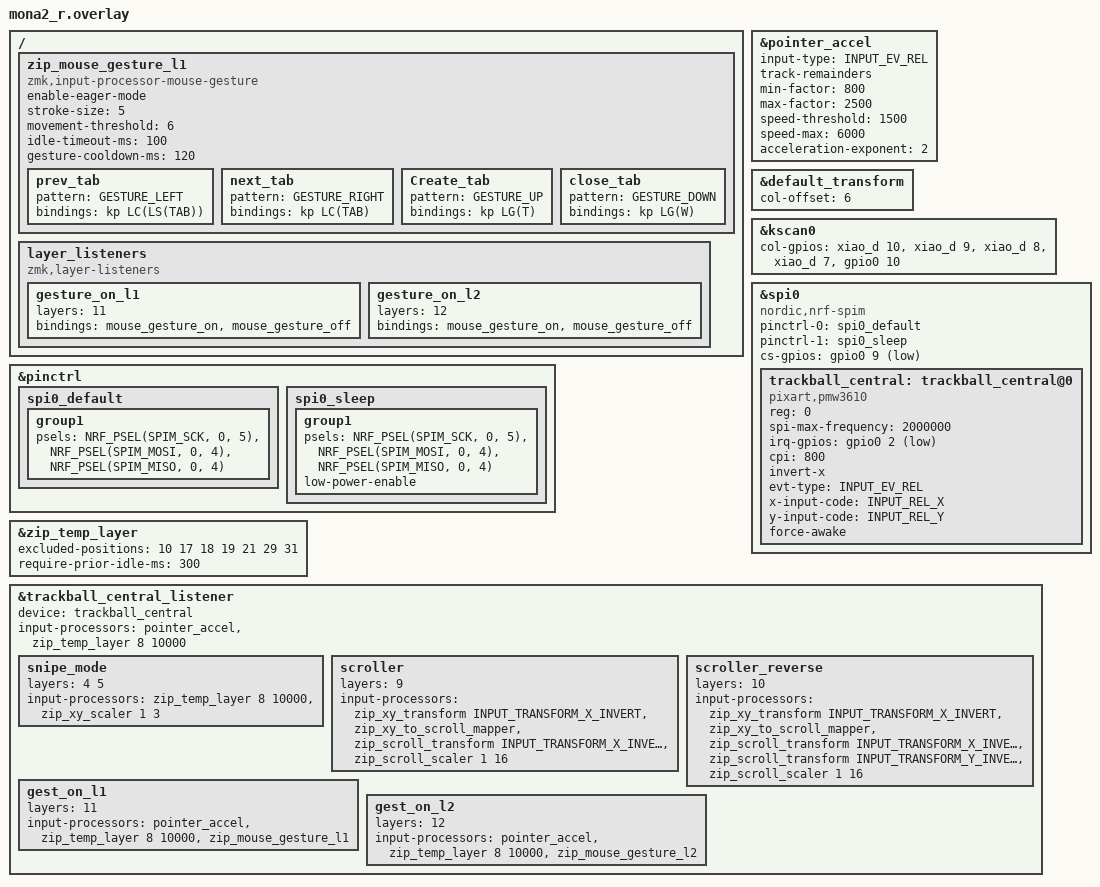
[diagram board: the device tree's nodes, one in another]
#include "mona2.dtsi"
#include <input/processors.dtsi>
#include <zephyr/dt-bindings/input/input-event-codes.h>
#include <input/processors.dtsi>
#include <behaviors/input_gestures_accel.dtsi>
#include <mouse-gesture.dtsi>   /* kot149 モジュール */

// =========================================================================
// ジェスチャーモジュールの定義（ここが重要です）
// =========================================================================
/ {
    zip_mouse_gesture_l1: zip_mouse_gesture_l1 {
        compatible = "zmk,input-processor-mouse-gesture";
        #input-processor-cells = <0>; 
        enable-eager-mode;
        stroke-size = <5>;
        movement-threshold = <6>;
        idle-timeout-ms = <100>;
        gesture-cooldown-ms = <120>;

        prev_tab    { pattern = <GESTURE_LEFT>;  bindings = <&kp LC(LS(TAB))>; };
        next_tab    { pattern = <GESTURE_RIGHT>; bindings = <&kp LC(TAB)>;     };
        Create_tab  { pattern = <GESTURE_UP>;    bindings = <&kp LG(T)>;       };
        close_tab   { pattern = <GESTURE_DOWN>;  bindings = <&kp LG(W)>;       };
    };
};

// =========================================================================
// ★追加：加速度（アクセラレーション）のカーブ設定
// =========================================================================
&pointer_accel {
    input-type = <INPUT_EV_REL>;
    track-remainders;
    min-factor = <800>;
    max-factor = <2500>;
    speed-threshold = <1500>;
    speed-max = <6000>;
    acceleration-exponent = <2>;
};

&default_transform {
    col-offset = <6>;
};

&kscan0 {
        col-gpios
            = <&xiao_d 10 GPIO_ACTIVE_HIGH>
            , <&xiao_d 9 GPIO_ACTIVE_HIGH> 
            , <&xiao_d 8 GPIO_ACTIVE_HIGH> 
            , <&xiao_d 7 GPIO_ACTIVE_HIGH> 
            , <&gpio0 10 GPIO_ACTIVE_HIGH>
            ;
};

&pinctrl {
    spi0_default: spi0_default {
        group1 {
            psels = <NRF_PSEL(SPIM_SCK, 0, 5)>,
                <NRF_PSEL(SPIM_MOSI, 0, 4)>,
                <NRF_PSEL(SPIM_MISO, 0, 4)>;
        };
    };

    spi0_sleep: spi0_sleep {
        group1 {
            psels = <NRF_PSEL(SPIM_SCK, 0, 5)>,
                <NRF_PSEL(SPIM_MOSI, 0, 4)>,
                <NRF_PSEL(SPIM_MISO, 0, 4)>;
            low-power-enable;
        };
    };
};

&spi0 {
    status = "okay";
    compatible = "nordic,nrf-spim";
    pinctrl-0 = <&spi0_default>;
    pinctrl-1 = <&spi0_sleep>;
    pinctrl-names = "default", "sleep";
    cs-gpios = <&gpio0 9 GPIO_ACTIVE_LOW>;

    trackball_central: trackball_central@0 {
        status = "okay";
        compatible = "pixart,pmw3610";
        reg = <0>;
        spi-max-frequency = <2000000>;
        irq-gpios = <&gpio0 2 (GPIO_ACTIVE_LOW | GPIO_PULL_UP)>;
        cpi = <800>;
        invert-x;
        evt-type = <INPUT_EV_REL>;
        x-input-code = <INPUT_REL_X>;
        y-input-code = <INPUT_REL_Y>;
        force-awake;
    };
};

&zip_temp_layer {
    excluded-positions = <10 17 18 19 21 29 31>;
    require-prior-idle-ms = <300>;
};

&trackball_central_listener {
    status = "okay";
    device = <&trackball_central>;

    input-processors = <&pointer_accel &zip_temp_layer 8 10000>;

    snipe_mode {
        layers = <4 5>;
        input-processors = <&zip_temp_layer 8 10000>, <&zip_xy_scaler 1 3>;
    };

    scroller {
        layers = <9>;
        input-processors = <&zip_xy_transform INPUT_TRANSFORM_X_INVERT>,
                           <&zip_xy_to_scroll_mapper>,
                           <&zip_scroll_transform INPUT_TRANSFORM_X_INVERT>,
                           <&zip_scroll_scaler 1 16>;
    };

    scroller_reverse {
        layers = <10>;
        input-processors = <&zip_xy_transform INPUT_TRANSFORM_X_INVERT>,
                           <&zip_xy_to_scroll_mapper>,
                           <&zip_scroll_transform INPUT_TRANSFORM_X_INVERT>,
                           <&zip_scroll_transform INPUT_TRANSFORM_Y_INVERT>,
                           <&zip_scroll_scaler 1 16>;
    };

    // レイヤー11用のジェスチャー設定（デフォルト処理と結合）
    gest_on_l1 {
        layers = <11>;
        input-processors = <&pointer_accel &zip_temp_layer 8 10000 &zip_mouse_gesture_l1>;
    };

    gest_on_l2 {
        layers = <12>;
        input-processors = <&pointer_accel &zip_temp_layer 8 10000 &zip_mouse_gesture_l2>;
    };
};

/ {
    layer_listeners {
        compatible = "zmk,layer-listeners";
        gesture_on_l1 {
            layers = <11>;
            bindings = <&mouse_gesture_on &mouse_gesture_off>;
        };
        gesture_on_l2 {
            layers = <12>;
            bindings = <&mouse_gesture_on &mouse_gesture_off>;
        };
   };
};
